VERSION ""

NS_ :

BS_:

BU_: PTC HVH

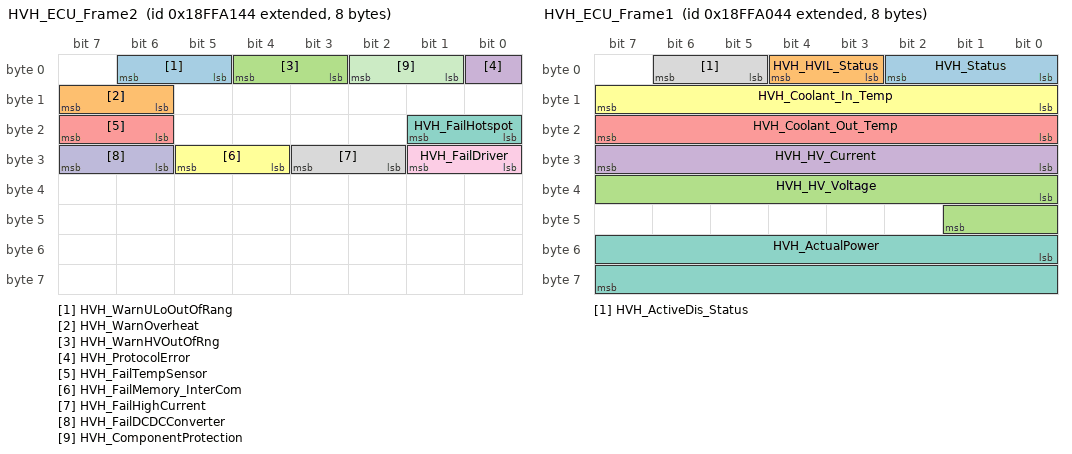
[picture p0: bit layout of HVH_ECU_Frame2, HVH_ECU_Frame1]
BO_ 2566889796 HVH_ECU_Frame2: 8 PTC
 SG_ HVH_WarnULoOutOfRang : 5|2@1+ (1,0) [0|3] ""  HVH
 SG_ HVH_WarnOverheat : 14|2@1+ (1,0) [0|3] ""  HVH
 SG_ HVH_WarnHVOutOfRng : 3|2@1+ (1,0) [0|3] ""  HVH
 SG_ HVH_ProtocolError : 0|1@1+ (1,0) [0|1] ""  HVH
 SG_ HVH_FailTempSensor : 22|2@1+ (1,0) [0|3] ""  HVH
 SG_ HVH_FailMemory_InterCom : 28|2@1+ (1,0) [0|3] ""  HVH
 SG_ HVH_FailHotspot : 16|2@1+ (1,0) [0|3] ""  HVH
 SG_ HVH_FailHighCurrent : 26|2@1+ (1,0) [0|3] ""  HVH
 SG_ HVH_FailDriver : 24|2@1+ (1,0) [0|3] ""  HVH
 SG_ HVH_FailDCDCConverter : 30|2@1+ (1,0) [0|3] ""  HVH
 SG_ HVH_ComponentProtection : 1|2@1+ (1,0) [0|3] ""  HVH

BO_ 2566889540 HVH_ECU_Frame1: 8 PTC
 SG_ HVH_Status : 0|3@1+ (1,0) [0|7] ""  HVH
 SG_ HVH_HVIL_Status : 3|2@1+ (1,0) [0|3] ""  HVH
 SG_ HVH_HV_Voltage : 32|10@1+ (1,0) [0|1023] "V"  HVH
 SG_ HVH_HV_Current : 24|8@1+ (0.25,0) [0|63.75] "A"  HVH
 SG_ HVH_Coolant_Out_Temp : 16|8@1+ (1,-50) [-50|205] "℃"  HVH
 SG_ HVH_Coolant_In_Temp : 8|8@1+ (1,-50) [-50|205] "℃"  HVH
 SG_ HVH_ActualPower : 48|16@1+ (1,0) [0|65535] "W"  HVH
 SG_ HVH_ActiveDis_Status : 5|2@1+ (1,0) [0|3] ""  HVH

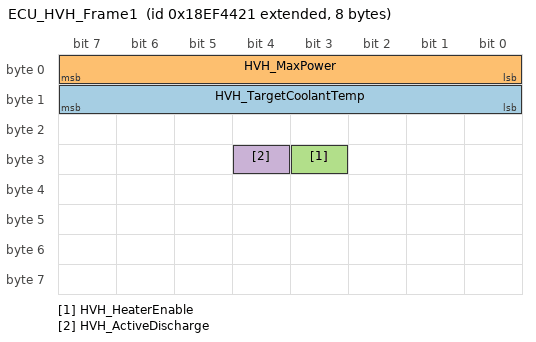
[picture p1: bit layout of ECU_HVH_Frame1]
BO_ 2565817377 ECU_HVH_Frame1: 8 HVH
 SG_ HVH_TargetCoolantTemp : 8|8@1+ (1,-50) [0|205] "℃"  PTC
 SG_ HVH_MaxPower : 0|8@1+ (100,0) [0|25500] "W"  PTC
 SG_ HVH_HeaterEnable : 27|1@1+ (1,0) [0|1] ""  PTC
 SG_ HVH_ActiveDischarge : 28|1@1+ (1,0) [0|1] ""  PTC

CM_ SG_ 2566889796 HVH_WarnULoOutOfRang "低压欠过压";
CM_ SG_ 2566889796 HVH_WarnOverheat "内部过热警告";
CM_ SG_ 2566889796 HVH_WarnHVOutOfRng "高压欠过压";
CM_ SG_ 2566889796 HVH_ProtocolError "CAN通讯故障";
CM_ SG_ 2566889796 HVH_FailTempSensor "温度传感器失效";
CM_ SG_ 2566889796 HVH_FailMemory_InterCom "内部存储器故障";
CM_ SG_ 2566889796 HVH_FailHotspot "水温过热警告";
CM_ SG_ 2566889796 HVH_FailHighCurrent "高压电流过流";
CM_ SG_ 2566889796 HVH_FailDriver "IGBT故障";
CM_ SG_ 2566889796 HVH_FailDCDCConverter "DCDC电源故障";
CM_ SG_ 2566889796 HVH_ComponentProtection "加热组件保护";
CM_ SG_ 2566889540 HVH_Status "运行状态";
CM_ SG_ 2566889540 HVH_HVIL_Status "高压互锁状态";
CM_ SG_ 2566889540 HVH_HV_Voltage "高压电压";
CM_ SG_ 2566889540 HVH_HV_Current "高压电流";
CM_ SG_ 2566889540 HVH_Coolant_Out_Temp "冷却液出口温度";
CM_ SG_ 2566889540 HVH_Coolant_In_Temp "冷却液入口温度";
CM_ SG_ 2566889540 HVH_ActualPower "实际功率";
CM_ SG_ 2566889540 HVH_ActiveDis_Status "主动放电状态";
CM_ SG_ 2565817377 HVH_TargetCoolantTemp "目标温度";
CM_ SG_ 2565817377 HVH_MaxPower "最大请求功率";
CM_ SG_ 2565817377 HVH_HeaterEnable "加热使能";
CM_ SG_ 2565817377 HVH_ActiveDischarge "主动放电使能";
BA_DEF_ BO_  "GenMsgCycleTime" INT 0 0;
BA_DEF_ BO_  "GenMsgSendType" ENUM  "Cyclic","NotUsed","NotUsed","NotUsed","NotUsed","NotUsed","NotUsed","IfActive","NoMsgSendType","NotUsed";
BA_DEF_ SG_  "GenSigStartValue" INT 0 0;
BA_DEF_ SG_  "GenSigSendType" ENUM  "Cyclic","OnWrite","OnWriteWithRepetition","OnChange","OnChangeWithRepetition","IfActive","IfActiveWithRepetition","NoSigSendType","NotUsed","NotUsed","NotUsed","NotUsed","NotUsed";
BA_DEF_  "Baudrate" INT 0 1000000;
BA_DEF_  "BusType" STRING ;
BA_DEF_  "Manufacturer" STRING ;
BA_DEF_ BU_  "NodeLayerModules" STRING ;
BA_DEF_  "NmAsrWaitBusSleepTime" INT 0 65535;
BA_DEF_  "NmAsrTimeoutTime" INT 1 65535;
BA_DEF_  "NmAsrRepeatMessageTime" INT 0 65535;
BA_DEF_ BU_  "NmAsrNodeIdentifier" HEX 0 255;
BA_DEF_  "NmAsrMessageCount" INT 1 256;
BA_DEF_ BU_  "NmAsrCanMsgReducedTime" INT 1 65535;
BA_DEF_  "NmAsrCanMsgCycleTime" INT 1 65535;
BA_DEF_  "NmAsrBaseAddress" HEX 0 2047;
BA_DEF_  "DBName" STRING ;
BA_DEF_DEF_  "GenMsgCycleTime" 0;
BA_DEF_DEF_  "GenMsgSendType" "Cyclic";
BA_DEF_DEF_  "GenSigStartValue" 0;
BA_DEF_DEF_  "GenSigSendType" "Cyclic";
BA_DEF_DEF_  "Baudrate" 500000;
BA_DEF_DEF_  "BusType" "";
BA_DEF_DEF_  "Manufacturer" "Vector";
BA_DEF_DEF_  "NodeLayerModules" " ";
BA_DEF_DEF_  "NmAsrWaitBusSleepTime" 1500;
BA_DEF_DEF_  "NmAsrTimeoutTime" 2000;
BA_DEF_DEF_  "NmAsrRepeatMessageTime" 3200;
BA_DEF_DEF_  "NmAsrNodeIdentifier" 50;
BA_DEF_DEF_  "NmAsrMessageCount" 128;
BA_DEF_DEF_  "NmAsrCanMsgReducedTime" 320;
BA_DEF_DEF_  "NmAsrCanMsgCycleTime" 640;
BA_DEF_DEF_  "NmAsrBaseAddress" 1280;
BA_DEF_DEF_  "DBName" "";
BA_ "Baudrate" 250000;
BA_ "BusType" "CAN";
BA_ "DBName" "CAN";
BA_ "GenMsgCycleTime" BO_ 2566889796 100;
BA_ "GenMsgCycleTime" BO_ 2566889540 100;
BA_ "GenMsgCycleTime" BO_ 2565817377 100;
BA_ "GenSigStartValue" SG_ 2565817377 HVH_TargetCoolantTemp 50;
VAL_ 2566889796 HVH_WarnULoOutOfRang 3 "SNA" 2 "OverVoltage" 1 "UnderVoltage" 0 "No lssue" ;
VAL_ 2566889796 HVH_WarnOverheat 3 "SNA" 2 "OverheatCoolant" 1 "OverheatHC" 0 "No lssue" ;
VAL_ 2566889796 HVH_WarnHVOutOfRng 3 "SNA" 2 "OverVoltage" 1 "UnderVoltage" 0 "No lssue" ;
VAL_ 2566889796 HVH_ProtocolError 1 "TRUE" 0 "FALSE" ;
VAL_ 2566889796 HVH_FailTempSensor 3 "SNA" 2 "Not used" 1 "Defect" 0 "No lssue" ;
VAL_ 2566889796 HVH_FailMemory_InterCom 3 "SNA" 2 "Not used" 1 "Defect" 0 "No lssue" ;
VAL_ 2566889796 HVH_FailHotspot 3 "SNA" 2 "Not used" 1 "Defect" 0 "No lssue" ;
VAL_ 2566889796 HVH_FailHighCurrent 3 "SNA" 2 "Not used" 1 "Defect" 0 "No lssue" ;
VAL_ 2566889796 HVH_FailDriver 3 "SNA" 2 "Not used" 1 "Defect" 0 "No lssue" ;
VAL_ 2566889796 HVH_FailDCDCConverter 3 "SNA" 2 "Not used" 1 "Defect" 0 "No lssue" ;
VAL_ 2566889796 HVH_ComponentProtection 3 "OutletTemperature" 2 "InletTemperature" 1 "HeaterCoreTemperalure" 0 "Normal operalion" ;
VAL_ 2566889540 HVH_Status 7 "ActiveDischarge" 6 "Reserved" 5 "Production_Mode" 4 "Operation" 3 "PermanentLock" 2 "Reserved" 1 "TemporaryLock" 0 "Off" ;
VAL_ 2566889540 HVH_HVIL_Status 3 "SNA" 2 "OverVoltage" 1 "Disconnected" 0 "Connected" ;
VAL_ 2566889540 HVH_ActiveDis_Status 3 "Failed" 2 "Completed" 1 "Busy" 0 "OFF" ;
VAL_ 2565817377 HVH_HeaterEnable 1 "Enable" 0 "Disable" ;
VAL_ 2565817377 HVH_ActiveDischarge 1 "Enable" 0 "Disable" ;
